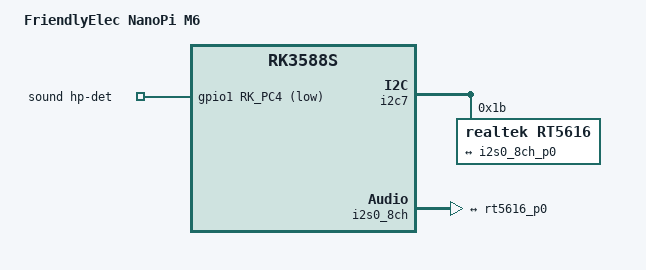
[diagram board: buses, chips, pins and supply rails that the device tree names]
// SPDX-License-Identifier: (GPL-2.0+ OR MIT)

/dts-v1/;

#include "rk3588s-nanopi-m6.dtsi"

/ {
	model = "FriendlyElec NanoPi M6";
	compatible = "friendlyarm,nanopi-m6", "rockchip,rk3588s";

	sound {
		compatible = "simple-audio-card";
		pinctrl-names = "default";
		pinctrl-0 = <&hp_det>;

		simple-audio-card,name = "realtek,rt5616-codec";
		simple-audio-card,format = "i2s";
		simple-audio-card,mclk-fs = <256>;

		simple-audio-card,hp-det-gpios = <&gpio1 RK_PC4 GPIO_ACTIVE_LOW>;

		simple-audio-card,widgets =
			"Headphone", "Headphones",
			"Microphone", "Microphone Jack";
		simple-audio-card,routing =
			"Headphones", "HPOL",
			"Headphones", "HPOR",
			"MIC1", "Microphone Jack",
			"Microphone Jack", "micbias1";

		simple-audio-card,cpu {
			sound-dai = <&i2s0_8ch>;
		};

		simple-audio-card,codec {
			sound-dai = <&rt5616>;
		};
	};
};

&i2c7 {
	rt5616: codec@1b {
		compatible = "realtek,rt5616";
		reg = <0x1b>;
		clocks = <&cru I2S0_8CH_MCLKOUT_TO_IO>;
		clock-names = "mclk";
		#sound-dai-cells = <0>;
		assigned-clocks = <&cru I2S0_8CH_MCLKOUT_TO_IO>;
		assigned-clock-rates = <12288000>;

		port {
			rt5616_p0: endpoint {
				remote-endpoint = <&i2s0_8ch_p0>;
			};
		};
	};
};

&i2s0_8ch {
	port {
		i2s0_8ch_p0: endpoint {
			dai-format = "i2s";
			mclk-fs = <256>;
			remote-endpoint = <&rt5616_p0>;
		};
	};
};
